# ARMv8M-Baseline register map
Registers are read-only, no defined reset value unless marked. A register's access mark holds for its fields unless they carry their own. Offsets are from the block's base; [hi:lo] are bit positions; {n}, {i} and the like mark numbered series.

## ITM — Instrumentation Macrocell
Base 0xE0000000
0x00 STIM rw — ITM Stimulus Port Register provides the interface for generating Instrumentation packets
  [1] DISABLED — Disabled. Indicates whether the stimulus port is enabled or disabled
    0=Stimulus port and ITM are enabled; 1=Stimulus port or ITM is disabled
  [31:0] STIMULUS — Stimulus data
  [0] FIFOREADY — FIFO ready. Indicates whether the stimulus port can accept data
    0=Stimulus port cannot accept data; 1=Stimulus port can accept at least one word
{0xE00+4i} ITM_TER[{i}] (i=0..6) rw — Trace Enable Register provides an individual enable bit for each STIM register
  [n+31:n] STIMENA[{n}] (n=0..31) — Stimulus enable
    0=Stimulus port (32n + m) disabled; 1=Stimulus port (32n + m) enabled
0xE40 ITM_TPR rw — ITM Trace Privilege Register controls which stimulus ports can be accessed by unprivileged code
  [31:0] PRIVMASK — Privilege mask
    0=Unprivileged access permitted; 1=Privileged access only
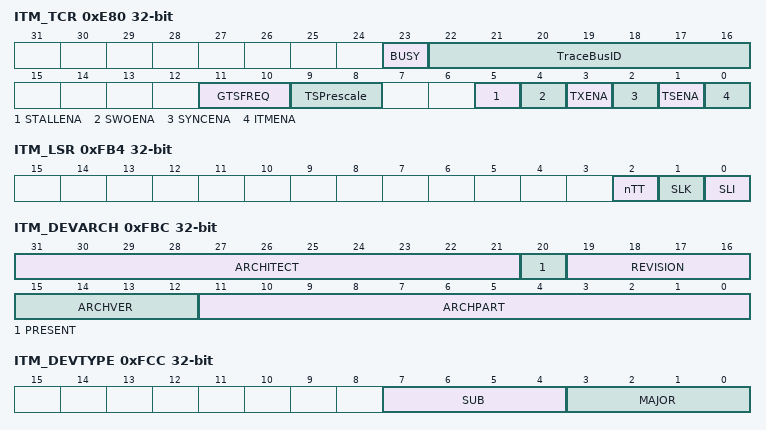
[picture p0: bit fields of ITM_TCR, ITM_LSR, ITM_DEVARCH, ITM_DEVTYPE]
0xE80 ITM_TCR rw — ITM Trace Control Register configures and controls transfers through the ITM interface
  [23] BUSY — ITM busy. Indicates whether the ITM is currently processing events
    0=ITM is not processing any events; 1=Events present and being drained
  [22:16] TraceBusID — Trace bus identity. Identifier for multi-source trace stream formatting
    0=Multi-source trace not in use
  [11:10] GTSFREQ — Global timestamp frequency
    0=Disable generation of Global Timestamp packets; 1=Generate timestamp request whenever the ITM detects a change in global timestamp counter bits [47:7]; 2=Generate timestamp request whenever the ITM detects a change in global timestamp counter bits [47:13]; 3=Generate a timestamp after every packet, if the output FIFO is empty
  [9:8] TSPrescale — Timestamp prescale. Local timestamp prescaler, used with the trace packet reference clock
    0=No prescaling; 1=Divide by 4; 2=Divide by 16; 3=Divide by 64
  [5] STALLENA — Stall enable. Stall the PE to guarantee delivery of Data Trace packets
    0=Drop Hardware Source packets and generate an Overflow packet if the ITM output is stalled; 1=Stall the PE to guarantee delivery of Data Trace packets
  [4] SWOENA — SWO enable. Enables asynchronous clocking of the timestamp counter
    0=Timestamp counter uses the processor system clock; 1=Timestamp counter uses asynchronous clock from the TPIU interface
  [3] TXENA — Transmit enable
    0=Disabled; 1=Enabled
  [2] SYNCENA — Synchronization enable. Enables Synchronization packet transmission for a synchronous TPIU
    0=Disabled; 1=Enabled
  [1] TSENA — Timestamp enable. Enables Local timestamp generation
    0=Disabled; 1=Enabled
  [0] ITMENA — ITM enable. Enables the ITM
    0=Disabled; 1=Enabled
0xFB0 ITM_LAR wo — ITM Software Lock Access Register provides CoreSight Software Lock control for the ITM, see the CoreSight Architecture Specification for details
  [31:0] KEY — Lock Access control
0xFB4 ITM_LSR — ITM Software Lock Status Register provides CoreSight Software Lock status information for the ITM, see the CoreSight Architecture Specification for details
  [2] nTT — Not thirty-two bit. See the CoreSight Architecture Specification
  [1] SLK — Software Lock status. See the CoreSight Architecture Specification
    0=Lock clear. Software writes are permitted to this component's registers; 1=Lock set
  [0] SLI — Software Lock implemented. See the CoreSight Architecture Specification
    0=Software Lock not implemented or debugger access; 1=Software Lock is implemented and software access
0xFBC ITM_DEVARCH — ITM Device Architecture Register provides CoreSight discovery information for the ITM
  [31:21] ARCHITECT — Architect. Defines the architect of the component
    0x23B=JEP106 continuation code 0x4, ID code 0x3B. ARM Limited
  [20] PRESENT — DEVARCH Present. Defines that the DEVARCH register is present
    1=DEVARCH information present
  [19:16] REVISION — Revision. Defines the architecture revision of the component
    0=ITM architecture v2.0
  [15:12] ARCHVER — Architecture Version. Defines the architecture version of the component
    1=ITM architecture v2
  [11:0] ARCHPART — Architecture Part. Defines the architecture of the component
    0xA01=ITM architecture
0xFCC ITM_DEVTYPE — ITM Device Type Register provides CoreSight discovery information for the ITM
  [7:4] SUB — Subtype. Component subtype
    0=Other. Only permitted if the MAJOR field reads as 0x0; 4=Associated with a Bus, stimulus derived from bus activity
  [3:0] MAJOR — Major type. Component major type
    0=Miscellaneous; 3=Trace Source
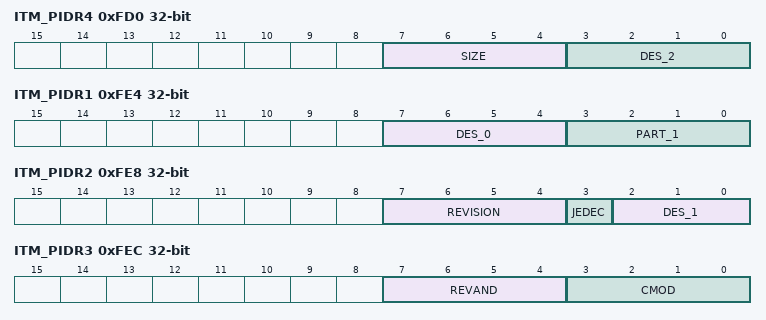
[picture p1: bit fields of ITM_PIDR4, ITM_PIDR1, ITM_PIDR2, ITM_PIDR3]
0xFD0 ITM_PIDR4 — ITM Peripheral Identification Register 4 provides CoreSight discovery information for the ITM
  [7:4] SIZE — 4KB count. See the CoreSight Architecture Specification
  [3:0] DES_2 — JEP106 continuation code. See the CoreSight Architecture Specification
{0xFC0+4i} ITM_PIDR{i} (i=5..7) — ITM Peripheral Identification Register {i} provides CoreSight discovery information for the ITM
0xFE0 ITM_PIDR0 — ITM Peripheral Identification Register 0 provides CoreSight discovery information for the ITM
  [7:0] PART_0 — Part number bits [7:0]. See the CoreSight Architecture Specification
0xFE4 ITM_PIDR1 — ITM Peripheral Identification Register 1 provides CoreSight discovery information for the ITM
  [7:4] DES_0 — JEP106 identification code bits [3:0]. See the CoreSight Architecture Specification
  [3:0] PART_1 — Part number bits [11:8]. See the CoreSight Architecture Specification
0xFE8 ITM_PIDR2 — ITM Peripheral Identification Register 2 provides CoreSight discovery information for the ITM
  [7:4] REVISION — Component revision. See the CoreSight Architecture Specification
  [3] JEDEC — JEDEC assignee value is used. See the CoreSight Architecture Specification
  [2:0] DES_1 — JEP106 identification code bits [6:4]. See the CoreSight Architecture Specification
0xFEC ITM_PIDR3 — ITM Peripheral Identification Register 3 provides CoreSight discovery information for the ITM
  [7:4] REVAND — RevAnd. See the CoreSight Architecture Specification
  [3:0] CMOD — Customer Modified. See the CoreSight Architecture Specification
0xFF0 ITM_CIDR0 — ITM Component Identification Register 0 provides CoreSight discovery information for the ITM
  [7:0] PRMBL_0 — CoreSight component identification preamble
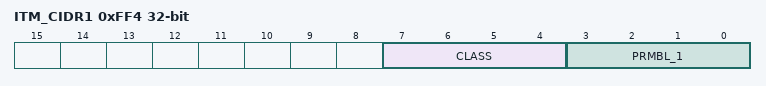
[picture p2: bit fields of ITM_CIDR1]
0xFF4 ITM_CIDR1 — ITM Component Identification Register 1 provides CoreSight discovery information for the ITM
  [7:4] CLASS — CoreSight component class. See the CoreSight Architecture Specification
  [3:0] PRMBL_1 — CoreSight component identification preamble
0xFF8 ITM_CIDR2 — ITM Component Identification Register 2 provides CoreSight discovery information for the ITM
  [7:0] PRMBL_2 — CoreSight component identification preamble
0xFFC ITM_CIDR3 — ITM Component Identification Register 3 provides CoreSight discovery information for the ITM
  [7:0] PRMBL_3 — CoreSight component identification preamble
